VERSION ""

NS_ :

BS_:

BU_: FC PC

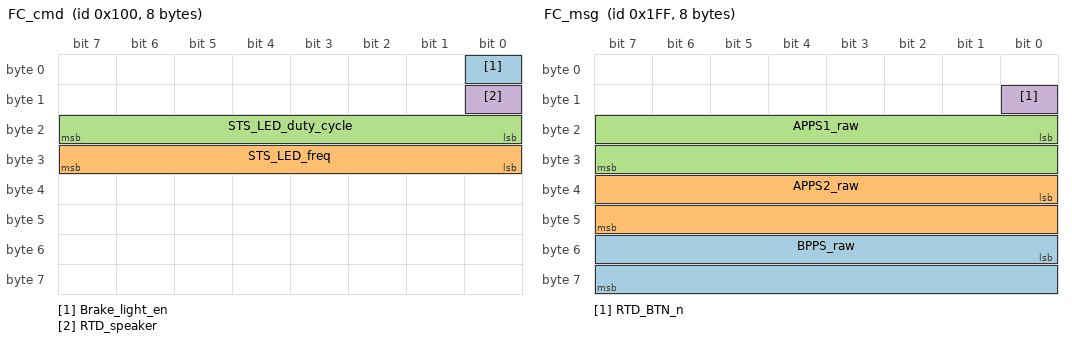
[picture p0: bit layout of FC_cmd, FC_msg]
BO_ 256 FC_cmd: 8 PC
 SG_ Brake_light_en : 0|1@1+ (1,0) [0|1] ""  FC
 SG_ STS_LED_freq : 24|8@1+ (1,0) [0|255] ""  FC
 SG_ STS_LED_duty_cycle : 16|8@1+ (1,0) [0|255] ""  FC
 SG_ RTD_speaker : 8|1@1+ (1,0) [0|1] ""  FC

BO_ 511 FC_msg: 8 FC
 SG_ BPPS_raw : 48|16@1+ (1,0) [0|4095] ""  PC
 SG_ APPS2_raw : 32|16@1+ (1,0) [0|4095] ""  PC
 SG_ APPS1_raw : 16|16@1+ (1,0) [0|4095] ""  PC
 SG_ RTD_BTN_n : 8|1@1+ (1,0) [0|1] ""  PC

CM_ BO_ 256 "Message send from host laptop to Front Controller";
CM_ SG_ 256 Brake_light_en "Brake light enable";
CM_ SG_ 256 STS_LED_freq "Status LED PWM frequency";
CM_ SG_ 256 STS_LED_duty_cycle "Status LED PWM duty cycle";
CM_ SG_ 256 RTD_speaker "Ready to drive speaker status";
CM_ BO_ 511 "Message transmit from Front Controller to host laptop";
CM_ SG_ 511 BPPS_raw "Brake pedal position raw value";
CM_ SG_ 511 APPS2_raw "Accelerator 2 raw value";
CM_ SG_ 511 APPS1_raw "Accelerator 1 raw value";
CM_ SG_ 511 RTD_BTN_n "Ready to drive button status, active low";
BA_DEF_  "BusType" STRING ;
BA_DEF_DEF_  "BusType" "CAN";
